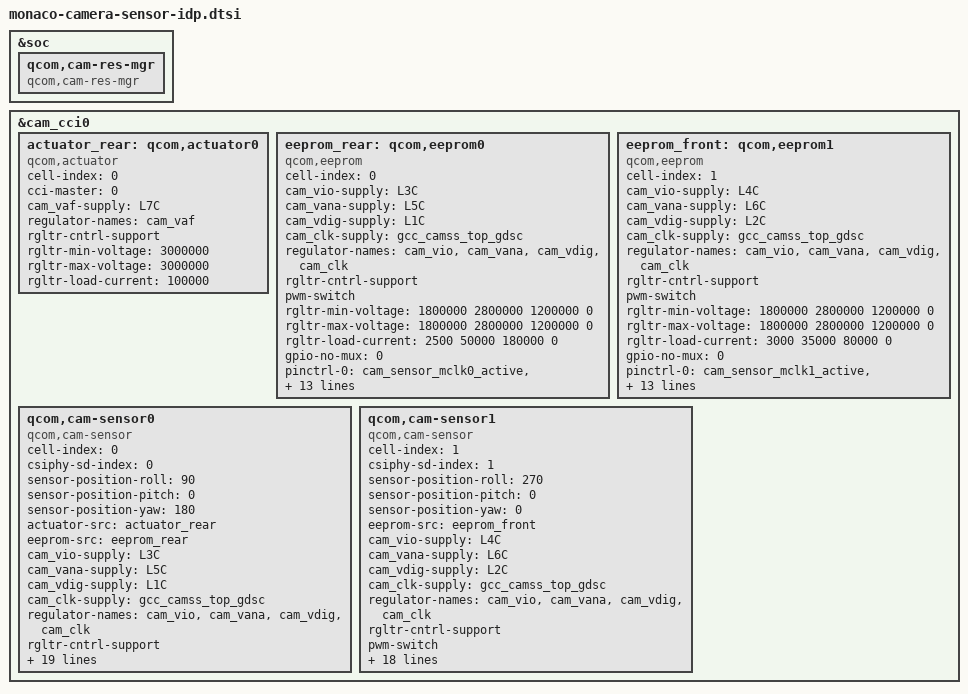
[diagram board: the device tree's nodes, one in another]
#include <dt-bindings/clock/qcom,gcc-monaco.h>
&soc {
	qcom,cam-res-mgr {
		compatible = "qcom,cam-res-mgr";
		status = "ok";
	};
};

&cam_cci0 {
	actuator_rear: qcom,actuator0 {
		cell-index = <0>;
		compatible = "qcom,actuator";
		cci-master = <0>;
		cam_vaf-supply = <&L7C>;
		regulator-names = "cam_vaf";
		rgltr-cntrl-support;
		rgltr-min-voltage = <3000000>;
		rgltr-max-voltage = <3000000>;
		rgltr-load-current = <100000>;
		status = "ok";
	};

	eeprom_rear: qcom,eeprom0 {
		cell-index = <0>;
		compatible = "qcom,eeprom";
		cam_vio-supply = <&L3C>;
		cam_vana-supply = <&L5C>;
		cam_vdig-supply = <&L1C>;
		cam_clk-supply = <&gcc_camss_top_gdsc>;
		regulator-names = "cam_vio", "cam_vana", "cam_vdig",
			"cam_clk";
		rgltr-cntrl-support;
		pwm-switch;
		rgltr-min-voltage = <1800000 2800000 1200000 0>;
		rgltr-max-voltage = <1800000 2800000 1200000 0>;
		rgltr-load-current = <2500 50000 180000 0>;
		gpio-no-mux = <0>;
		pinctrl-names = "cam_default", "cam_suspend";
		pinctrl-0 = <&cam_sensor_mclk0_active
				&cam_sensor_rear0_reset_active>;
		pinctrl-1 = <&cam_sensor_mclk0_suspend
				&cam_sensor_rear0_reset_suspend>;
		gpios = <&tlmm 32 0>,
			<&tlmm 35 0>;
		gpio-reset = <1>;
		gpio-req-tbl-num = <0 1>;
		gpio-req-tbl-flags = <1 0>;
		gpio-req-tbl-label = "CAMIF_MCLK0",
					"CAM_RESET0";
		sensor-mode = <0>;
		cci-master = <0>;
		status = "ok";
		clocks = <&gcc GCC_CAMSS_MCLK0_CLK>;
		clock-names = "cam_clk";
		clock-cntl-level = "turbo";
		clock-rates = <24000000>;
	};

	eeprom_front: qcom,eeprom1 {
		cell-index = <1>;
		compatible = "qcom,eeprom";
		cam_vio-supply = <&L4C>;
		cam_vana-supply = <&L6C>;
		cam_vdig-supply = <&L2C>;
		cam_clk-supply = <&gcc_camss_top_gdsc>;
		regulator-names = "cam_vio", "cam_vana", "cam_vdig",
			"cam_clk";
		rgltr-cntrl-support;
		pwm-switch;
		rgltr-min-voltage = <1800000 2800000 1200000 0>;
		rgltr-max-voltage = <1800000 2800000 1200000 0>;
		rgltr-load-current = <3000 35000 80000 0>;
		gpio-no-mux = <0>;
		pinctrl-names = "cam_default", "cam_suspend";
		pinctrl-0 = <&cam_sensor_mclk1_active
				&cam_sensor_front0_reset_active>;
		pinctrl-1 = <&cam_sensor_mclk1_suspend
				&cam_sensor_front0_reset_suspend>;
		gpios = <&tlmm 33 0>,
			<&tlmm 36 0>;
		gpio-reset = <1>;
		gpio-req-tbl-num = <0 1>;
		gpio-req-tbl-flags = <1 0>;
		gpio-req-tbl-label = "CAMIF_MCLK1",
					"CAM_RESET1";
		sensor-mode = <0>;
		cci-master = <1>;
		status = "ok";
		clocks = <&gcc GCC_CAMSS_MCLK1_CLK>;
		clock-names = "cam_clk";
		clock-cntl-level = "turbo";
		clock-rates = <24000000>;
	};

	/* Rear*/
	qcom,cam-sensor0 {
		cell-index = <0>;
		compatible = "qcom,cam-sensor";
		csiphy-sd-index = <0>;
		sensor-position-roll = <90>;
		sensor-position-pitch = <0>;
		sensor-position-yaw = <180>;
		actuator-src = <&actuator_rear>;
		eeprom-src = <&eeprom_rear>;
		cam_vio-supply = <&L3C>;
		cam_vana-supply = <&L5C>;
		cam_vdig-supply = <&L1C>;
		cam_clk-supply = <&gcc_camss_top_gdsc>;
		regulator-names = "cam_vio", "cam_vana", "cam_vdig",
			"cam_clk";
		rgltr-cntrl-support;
		pwm-switch;
		rgltr-min-voltage = <1800000 2800000 1200000 0>;
		rgltr-max-voltage = <1800000 2800000 1200000 0>;
		rgltr-load-current = <2500 50000 180000 0>;
		gpio-no-mux = <0>;
		pinctrl-names = "cam_default", "cam_suspend";
		pinctrl-0 = <&cam_sensor_mclk0_active
				&cam_sensor_rear0_reset_active>;
		pinctrl-1 = <&cam_sensor_mclk0_suspend
				&cam_sensor_rear0_reset_suspend>;
		gpios = <&tlmm 32 0>,
			<&tlmm 35 0>;
		gpio-reset = <1>;
		gpio-req-tbl-num = <0 1>;
		gpio-req-tbl-flags = <1 0>;
		gpio-req-tbl-label = "CAMIF_MCLK0",
					"CAM_RESET0";
		sensor-mode = <0>;
		cci-master = <0>;
		status = "ok";
		clocks = <&gcc GCC_CAMSS_MCLK0_CLK>;
		clock-names = "cam_clk";
		clock-cntl-level = "turbo";
		clock-rates = <24000000>;
	};

	/*Front*/
	qcom,cam-sensor1 {
		cell-index = <1>;
		compatible = "qcom,cam-sensor";
		csiphy-sd-index = <1>;
		sensor-position-roll = <270>;
		sensor-position-pitch = <0>;
		sensor-position-yaw = <0>;
		eeprom-src = <&eeprom_front>;
		cam_vio-supply = <&L4C>;
		cam_vana-supply = <&L6C>;
		cam_vdig-supply = <&L2C>;
		cam_clk-supply = <&gcc_camss_top_gdsc>;
		regulator-names = "cam_vio", "cam_vana", "cam_vdig",
			"cam_clk";
		rgltr-cntrl-support;
		pwm-switch;
		rgltr-min-voltage = <1800000 2800000 1200000 0>;
		rgltr-max-voltage = <1800000 2800000 1200000 0>;
		rgltr-load-current = <3000 35000 80000 0>;
		gpio-no-mux = <0>;
		pinctrl-names = "cam_default", "cam_suspend";
		pinctrl-0 = <&cam_sensor_mclk1_active
				&cam_sensor_front0_reset_active>;
		pinctrl-1 = <&cam_sensor_mclk1_suspend
				&cam_sensor_front0_reset_suspend>;
		gpios = <&tlmm 33 0>,
			<&tlmm 36 0>;
		gpio-reset = <1>;
		gpio-req-tbl-num = <0 1>;
		gpio-req-tbl-flags = <1 0>;
		gpio-req-tbl-label = "CAMIF_MCLK1",
					"CAM_RESET1";
		sensor-mode = <0>;
		cci-master = <1>;
		status = "ok";
		clocks = <&gcc GCC_CAMSS_MCLK1_CLK>;
		clock-names = "cam_clk";
		clock-cntl-level = "turbo";
		clock-rates = <24000000>;
	};
};
